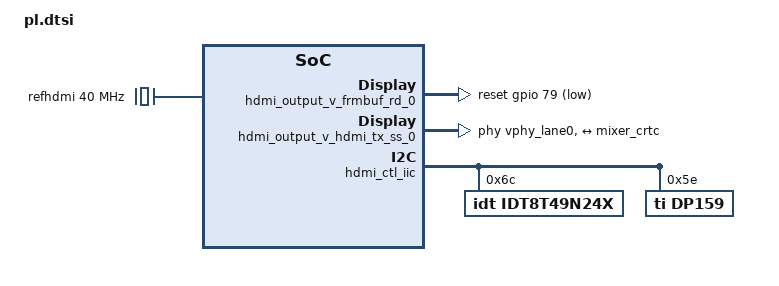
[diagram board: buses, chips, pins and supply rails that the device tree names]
/*
 * CAUTION: This file is automatically generated by Xilinx.
 * Version:
 * Today is: Tue Jul 24 03:37:50 2018
 */

/ {
	amba_pl: amba_pl@0 {
		#address-cells = <2>;
		#size-cells = <2>;
		compatible = "simple-bus";
		ranges ;
        hdmi_output_v_frmbuf_rd_0: v_frmbuf_rd@a2040000 {
                #dma-cells = <1>;
		clock-names = "ap_clk";
		clocks = <&misc_clk_0>;
		compatible = "xlnx,axi-frmbuf-rd-v2.1";
		interrupt-names = "interrupt";
                interrupt-parent = <&gic>;
                interrupts = <0 104 4>;
                reg = <0x0 0xa2040000 0x0 0x10000>;
                reset-gpios = <&gpio 79 1>;
		xlnx,dma-addr-width = <32>;
                xlnx,vid-formats = "bgr888","xbgr8888","xrgb8888","vuy888","xvuy8888","y8","yuyv","uyvy","nv16","nv12";
		xlnx,dma-align = <16>;
		xlnx,max-height = <2160>;
		xlnx,max-width = <3840>;
		xlnx,pixels-per-clock = <2>;
		xlnx,s-axi-ctrl-addr-width = <0x7>;
		xlnx,s-axi-ctrl-data-width = <0x20>;
		xlnx,video-width = <8>;
        };
	misc_clk_0: misc_clk_0 {
		#clock-cells = <0>;
		clock-frequency = <331896551>;
		compatible = "fixed-clock";
	};
        hdmi_output_v_hdmi_tx_ss_0: v_hdmi_tx_ss@a2020000 {
                compatible = "xlnx,v-hdmi-tx-ss-3.1";
                interrupt-parent = <&gic>;
                interrupts = <0 108 4>;
                interrupt-names = "hdmitx";
                reg = <0x0 0xa2020000 0x0 0x20000>;
                reg-names = "hdmi-txss";
                clocks = <&vid_s_axi_clk>, <&vid_stream_clk>, <&idt8t49n24x 2>, <&dp159>;
		clock-names = "s_axi_cpu_aclk", "s_axis_video_aclk", "txref-clk", "retimer-clk";
                phy-names = "hdmi-phy0", "hdmi-phy1", "hdmi-phy2";
                phys = <&vphy_lane0 0 1 1 1>, <&vphy_lane1 0 1 1 1>, <&vphy_lane2 0 1 1 1>;

                xlnx,input-pixels-per-clock = <0x2>;
                xlnx,max-bits-per-component = <0x8>;

                ports {
                        #address-cells = <1>;
                        #size-cells = <0>;
                        encoder_hdmi_port: port@0 {
                                reg = <0>;
                                hdmi_encoder: endpoint {
                                        remote-endpoint = <&mixer_crtc>;
                                };
                        };
                };
        };

	misc_clk_1: misc_clk_1 {
		#clock-cells = <0>;
		clock-frequency = <33333333>;
		compatible = "fixed-clock";
	};
	misc_clk_2: misc_clk_2 {
		#clock-cells = <0>;
		clock-frequency = <297000000>;
		compatible = "fixed-clock";
	};

        v_mix@a2070000 {
                compatible = "xlnx,mixer-4.0";
		clock-names = "ap_clk";
		clocks = <&misc_clk_0>;
                interrupt-parent = <&gic>;
                interrupts = <0 110 4>;
                reg = <0x0 0xa2070000 0x0 0x10000>;
                reset-gpios = <&gpio 98 1>;
                xlnx,dma-addr-width=<32>;
                xlnx,bpc = <0x8>;
                xlnx,ppc = <0x2>;
                xlnx,num-layers = <0xA>;

                mixer_port: port@0 {
	            reg = <0>;
        	    mixer_crtc: endpoint {
                	remote-endpoint = <&hdmi_encoder>;
	            };
        	};

                layer_0 {
                        xlnx,layer-id = <0x0>;
                        xlnx,vformat = "AR24";
/*                        xlnx,layer-streaming;
                        dmas = <&hdmi_output_v_frmbuf_rd_0 0>;
                        dma-names = "dma0";	*/
                        xlnx,layer-max-width = <0xf00>;
                        xlnx,layer-max-height = <0x870>;
			xlnx,layer-primary;
                };
       		layer_1 {
        	        xlnx,layer-id = <0x1>;
	                xlnx,vformat = "RG24";
                        xlnx,layer-max-width = <0xf00>;
           	};
                layer_2 {
                        xlnx,layer-id = <0x2>;
                        xlnx,vformat = "RG24";
                        xlnx,layer-max-width = <0xf00>;
                };
                layer_3 {
                        xlnx,layer-id = <0x3>;
                        xlnx,vformat = "RG24";
                        xlnx,layer-max-width = <0xf00>;
                };
		layer_4 {
            		xlnx,layer-id = <0x4>;
                	xlnx,vformat = "RG24";
                        xlnx,layer-max-width = <0xf00>;
                };
                layer_5 {
                        xlnx,layer-id = <0x5>;
                        xlnx,vformat = "RG24";
                        xlnx,layer-max-width = <0xf00>;
                };
                layer_6 {
                        xlnx,layer-id = <0x6>;
                        xlnx,vformat = "RG24";
                        xlnx,layer-max-width = <0xf00>;
                };
                layer_7 {
                        xlnx,layer-id = <0x7>;
                        xlnx,vformat = "RG24";
                        xlnx,layer-max-width = <0xf00>;
                };
                layer_8 {
                        xlnx,layer-id = <0x8>;
                        xlnx,vformat = "RG24";
                        xlnx,layer-max-width = <0xf00>;
                };
                layer_9 {
                        xlnx,layer-id = <0x9>;
                        xlnx,vformat = "RG24";
                        xlnx,layer-max-width = <0xf00>;
                };
                xv_mix_logo: logo {
                                xlnx,layer-id = <10>;
                                xlnx,logo-height = <256>;
                                xlnx,logo-width = <256>;
                                /* xlnx,logo-pixel-alpha; */
                };

        };
	ctrlfbwr: fbwr@0xa2000000 {
		compatible = "xlnx,ctrl-fbwr-1.0";
		reg = <0x0 0xa2000000 0x0 0x10000>;
                reset-gpios = <&gpio 82 1>;
	};
	ctrlfbrd: fbrd@0xa2010000 {
		compatible = "xlnx,ctrl-fbrd-1.0";
		reg = <0x0 0xa2010000 0x0 0x10000>;
                reset-gpios = <&gpio 81 1>;
	};
	ctrlvpss: vpss@0xa2200000 {
		compatible = "xlnx,ctrl-xvpss-1.1";
		reg = <0x0 0xa2200000 0x0 0x30000>;
                reset-gpios = <&gpio 80 1>;
		xlnx,vpss-taps = <6>;
		xlnx,vpss-ppc = <2>;
	};
	refhdmi: refhdmi {
		compatible = "fixed-clock";
		#clock-cells = <0>;
		clock-frequency = <40000000>;
	};
        hdmi_ctl_iic: i2c@a2050000 {
                #address-cells = <1>;
                #size-cells = <0>;
                status = "okay";
                compatible = "xlnx,xps-iic-2.00.a";
                interrupt-parent = <&gic>;
                interrupts = <0 109 4>;
                reg = <0x0 0xa2050000 0x0 0x1000>;
                clocks = <&vid_s_axi_clk>;
		clock-names = "s_axi_aclk";
		/* idt8t49n241 i2c clock generator */
		idt8t49n24x: clock-generator@6c {
			status = "okay";
			compatible = "idt,idt8t49n24x";
			#clock-cells = <1>;
			reg = <0x6c>;

			/* input clock(s); the XTAL is hard-wired on the ZCU104 board */
			clocks = <&refhdmi>;
			clock-names = "input-xtal";

			settings = [
				09 50 00 60 67 c5 6c 01 03 00 31 00 01 40 00 01 40 00 74 04 00 74 04 77 6d 00 00 00 00 00 00 ff
				ff ff ff 01 3f 00 2e 00 0d 00 00 00 01 00 00 d0 08 00 00 00 00 00 08 00 00 00 00 00 00 44 44 00
				00 00 00 00 00 00 00 00 00 00 00 00 00 00 00 00 00 00 00 00 00 00 00 00 00 00 00 00 00 00 00 00
				00 00 00 00 00 00 00 00 e9 0a 2b 20 00 00 00 0f 00 00 00 0e 00 00 0e 00 00 00 27 00 00 00 00 00
				00 00 00 00 00 00 00 00 00 00 00 00 00 00 00 00 00 00 00 00 00 00 00 00 00 00 00 00 00 00 00 00
				00 00 00 00 00 00 00 00 00 00 00 00 00 00 00 00 00 00 00 00 00 00 00 00 00 00 00 00 00 00 00 00
				00 00 00 00 00 00 00 00 00 00 00 00 00 00 00 00 00 00 00 00 00 00 00 00 00 00 00 00 00 00 00 00
				00 00 00 00 00 00 00 00 00 00 00 00 00 00 00 00 00 00 00 00 00 00 00 00 00 00 00 00 00 00 00 00
				00 00 00 00 00 00 00 00 00 00 00 00 00 00 00 00 00 00 00 00 00 00 00 00 00 00 00 00 00 00 00 00
				00 00 00 00 00 00 00 00 00 00 00 00 00 00 00 00 00 00 00 00 00 00 00 00 00 00 00 00 00 00 00 00
				00 00 00 00 00 00 00 00 00 00 00 00 00 00 00 00 00 00 00 00 00 00 00 00 00 00 00 00 00 00 00 00
				00 00 00 00 00 00 00 00 00 00 00 00 00 00 00 00 00 00 00 00 00 00 00 00 00 00 00 00 00 00 00 00
				00 00 00 00 00 00 00 00 00 00 00 00 00 00 00 00 00 00 00 00 00 00 00 00 00 00 00 00 00 00 00 00
				00 00 00 00 00 00 00 00 00 00 00 00 00 00 00 00 00 00 00 00 00 00 00 00 00 00 00 00 00 00 00 00
				00 00 00 00 00 00 00 00 00 00 00 00 00 00 00 00 00 00 00 00 00 00 00 00 00 00 00 00 00 00 00 00
				00 00 00 00 00 00 00 00 00 00 00 00 00 00 00 00 00 00 00 00 00 00 00 00 00 00 00 00 00 00 00 00
				e3 00 08 01 00 00 00 00 00 00 00 00 00 b0 00 00 00 0a 00 00 00 00 00 00 00 00 00 00 00 00 00 00
				00 00 00 00 00 00 00 00 00 00 00 00 00 00 00 00 00 00 00 00 00 00 00 00 00 00 00 00 00 00 00 00
				00 00 00 00 00 00 00 00 00 00 00 00 00 00 00 00 00 00 00 00 00 00 00 00 00 00 00 00 00 00 00 00
				00 00 00 00 00 00 00 00 00 00 00 00 00 00 00 00 00 00 00 00 00 00 00 00 00 00 00 00 00 00 00 00
				00 00 00 00 00 00 00 00 00 00 00 00 00 00 00 00 00 00 00 00 00 00 00 00 00 00 00 00 00 00 00 00
				00 00 00 00 00 00 00 00 00 00 00 00 00 00 00 00 00 00 00 00 00 00 00 00 00 00 00 00 00 00 00 00
				00 00 00 00 00 00 00 00 00 00 00 00 00 00 00 00 00 00 00 00 00 00 00 00 00 00 00 00 00 00 00 00
				00 00 00 00 00 00 00 00 00 00 00 00 00 00 00 00 00 00 00 00 00 00 00 00 00 00 00 00 00 00 00 00
				00 00 00 00 85 00 00 9c 01 d4 02 71 07 00 00 00 00 83 00 10 02 08 8c
				];
		};
                /* DP159 exposes a virtual CCF clock. Upon .set_rate(), it adapts its retiming/driving behaviour */
                dp159: hdmi-retimer@5e {
                        status = "okay";
                        compatible = "ti,dp159";
                        reg = <0x5e>;
                        #address-cells = <1>;
                        #size-cells = <0>;
                        #clock-cells = <0>;
                };
        };
	psu_ctrl_ipi: PERIPHERAL@ff380000 {
		compatible = "xlnx,PERIPHERAL-1.0";
		reg = <0x0 0xff380000 0x0 0x80000>;
	};
	psu_message_buffers: PERIPHERAL@ff990000 {
		compatible = "xlnx,PERIPHERAL-1.0";
		reg = <0x0 0xff990000 0x0 0x10000>;
	};
	vcu_0: vcu@a2100000 {
		#clock-cells = <1>;
		#address-cells = <2>;
		#size-cells = <2>;
		clock-names = "pll_ref", "aclk", "vcu_core_enc", "vcu_core_dec", "vcu_mcu_enc", "vcu_mcu_dec";
		clocks = <&misc_clk_1>, <&zynqmp_clk 71>, <&vcu_0 1>, <&vcu_0 2>, <&vcu_0 3>, <&vcu_0 4>;
		compatible = "xlnx,vcu-1.2", "xlnx,vcu";
		interrupt-names = "vcu_host_interrupt";
		interrupt-parent = <&gic>;
		interrupts = <0 111 4>;
		ranges ;
		reg = <0x0 0xa2140000 0x0 0x1000>,
			<0x0 0xa2141000 0x0 0x1000>;
		reg-names = "vcu_slcr", "logicore";
		/*encoder: al5e@a0100000 {
			compatible = "al,al5e-1.1", "al,al5e";
			interrupt-parent = <&gic>;
			interrupts = <0 96 4>;
			reg = <0x0 0xa0100000 0x0 0x10000>;
		};*/
		decoder: al5d@a0120000 {
			compatible = "al,al5d-1.1", "al,al5d";
			interrupt-parent = <&gic>;
			interrupts = <0 111 4>;
			reg = <0x0 0xa2120000 0x0 0x10000>;
		};
	};
        vid_stream_clk: vid_stream_clk {
                compatible = "fixed-clock";
                #clock-cells = <0>;
                clock-frequency = <300000000>;
        };

        vid_s_axi_clk: vid_s_axi_clk {
                compatible = "fixed-clock";
                #clock-cells = <0>;
                clock-frequency = <99990000>;
        };

	hdmi_dru_clk: clock-generator-hdmi-dru-clk {
		compatible = "fixed-clock";
		#clock-cells = <0>;
		clock-frequency = <156250000>;
	};
        vid_phy_controller: vid_phy_controller@a2060000 {
                compatible = "xlnx,vid-phy-controller-2.2";
                interrupt-parent = <&gic>;
                interrupts = <0 107 4>;
                reg = <0x0 0xa2060000 0x0 0x10000>;
                clocks = <&vid_s_axi_clk>, <&hdmi_dru_clk>;
		clock-names = "vid_phy_axi4lite_aclk", "dru-clk";

                xlnx,input-pixels-per-clock = <0x2>;
                xlnx,nidru = <0x1>;
                xlnx,nidru-refclk-sel = <0x5>;
                xlnx,rx-no-of-channels = <0x3>;
                xlnx,rx-pll-selection = <0x0>;
                xlnx,rx-protocol = <0x1>;
                xlnx,rx-refclk-sel = <0x1>;
                xlnx,tx-no-of-channels = <0x3>;
                xlnx,tx-pll-selection = <0x6>;
                xlnx,tx-protocol = <0x1>;
                xlnx,tx-refclk-sel = <0x0>;
                xlnx,hdmi-fast-switch = <0x1>;
                xlnx,transceiver-type = <0x5>;
                xlnx,tx-buffer-bypass = <0x1>;
                xlnx,transceiver-width = <0x2>;
		xlnx,use-gt-ch4-hdmi = <0>;

                vphy_lane0: vphy_lane@0 {
                        #phy-cells = <4>;
                };
                vphy_lane1: vphy_lane@1 {
                        #phy-cells = <4>;
                };
                vphy_lane2: vphy_lane@2 {
                        #phy-cells = <4>;
                };
                vphy_lane3: vphy_lane@3 {
                        #phy-cells = <4>;
                };
        };
	misc_clk_4: misc_clk_4 {
			#clock-cells = <0>;
			clock-frequency = <100000000>;
			compatible = "fixed-clock";
		};
	};
};
&sata {
	ceva,p0-burst-params = /bits/ 8 <0x13 0x08 0x4A 0x06>;
	ceva,p0-cominit-params = /bits/ 8 <0x18 0x40 0x18 0x28>;
	ceva,p0-comwake-params = /bits/ 8 <0x06 0x14 0x08 0x0E>;
	ceva,p0-retry-params = /bits/ 16 <0x96A4 0x3FFC>;
	ceva,p1-burst-params = /bits/ 8 <0x13 0x08 0x4A 0x06>;
	ceva,p1-cominit-params = /bits/ 8 <0x18 0x40 0x18 0x28>;
	ceva,p1-comwake-params = /bits/ 8 <0x06 0x14 0x08 0x0E>;
	ceva,p1-retry-params = /bits/ 16 <0x96A4 0x3FFC>;
};
